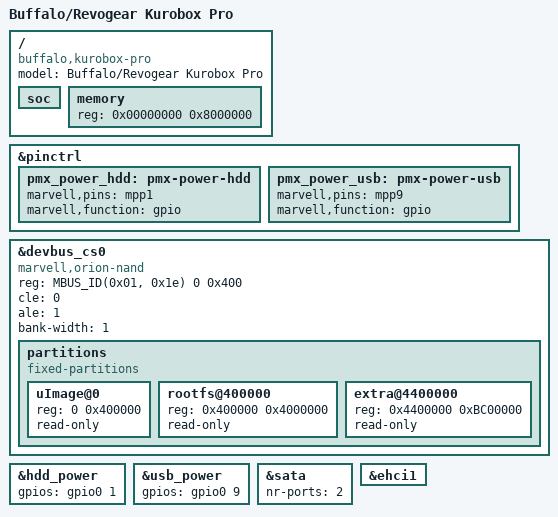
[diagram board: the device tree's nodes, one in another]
/*
 * Device Tree file for Buffalo/Revogear Kurobox Pro
 *
 * Copyright (C) 2016
 * Roger Shimizu <rogershimizu@gmail.com>
 *
 * Based on the board file arch/arm/mach-orion5x/kurobox_pro-setup.c
 * Copyright (C) Ronen Shitrit <rshitrit@marvell.com>
 *
 * This file is dual-licensed: you can use it either under the terms
 * of the GPL or the X11 license, at your option. Note that this dual
 * licensing only applies to this file, and not this project as a
 * whole.
 *
 *  a) This file is free software; you can redistribute it and/or
 *     modify it under the terms of the GNU General Public License as
 *     published by the Free Software Foundation; either version 2 of the
 *     License, or (at your option) any later version.
 *
 *     This file is distributed in the hope that it will be useful,
 *     but WITHOUT ANY WARRANTY; without even the implied warranty of
 *     MERCHANTABILITY or FITNESS FOR A PARTICULAR PURPOSE.  See the
 *     GNU General Public License for more details.
 *
 * Or, alternatively,
 *
 *  b) Permission is hereby granted, free of charge, to any person
 *     obtaining a copy of this software and associated documentation
 *     files (the "Software"), to deal in the Software without
 *     restriction, including without limitation the rights to use,
 *     copy, modify, merge, publish, distribute, sublicense, and/or
 *     sell copies of the Software, and to permit persons to whom the
 *     Software is furnished to do so, subject to the following
 *     conditions:
 *
 *     The above copyright notice and this permission notice shall be
 *     included in all copies or substantial portions of the Software.
 *
 *     THE SOFTWARE IS PROVIDED "AS IS", WITHOUT WARRANTY OF ANY KIND,
 *     EXPRESS OR IMPLIED, INCLUDING BUT NOT LIMITED TO THE WARRANTIES
 *     OF MERCHANTABILITY, FITNESS FOR A PARTICULAR PURPOSE AND
 *     NONINFRINGEMENT. IN NO EVENT SHALL THE AUTHORS OR COPYRIGHT
 *     HOLDERS BE LIABLE FOR ANY CLAIM, DAMAGES OR OTHER LIABILITY,
 *     WHETHER IN AN ACTION OF CONTRACT, TORT OR OTHERWISE, ARISING
 *     FROM, OUT OF OR IN CONNECTION WITH THE SOFTWARE OR THE USE OR
 *     OTHER DEALINGS IN THE SOFTWARE.
 */

/dts-v1/;

#include "orion5x-linkstation.dtsi"
#include <dt-bindings/gpio/gpio.h>

/ {
	model = "Buffalo/Revogear Kurobox Pro";
	compatible = "buffalo,kurobox-pro", "marvell,orion5x-88f5182", "marvell,orion5x";

	soc {
		ranges = <MBUS_ID(0xf0, 0x01) 0 0xf1000000 0x100000>,
				 <MBUS_ID(0x09, 0x00) 0 0xf2200000 0x800>,
				 <MBUS_ID(0x01, 0x0f) 0 0xf4000000 0x40000>,
				 <MBUS_ID(0x01, 0x1e) 0 0xfc000000 0x1000000>;
	};

	memory { /* 128 MB */
		device_type = "memory";
		reg = <0x00000000 0x8000000>;
	};
};

&pinctrl {
	pmx_power_hdd: pmx-power-hdd {
		marvell,pins = "mpp1";
		marvell,function = "gpio";
	};

	pmx_power_usb: pmx-power-usb {
		marvell,pins = "mpp9";
		marvell,function = "gpio";
	};
};

&devbus_cs0 {
	status = "okay";
	compatible = "marvell,orion-nand";
	reg = <MBUS_ID(0x01, 0x1e) 0 0x400>;
	cle = <0>;
	ale = <1>;
	bank-width = <1>;

	partitions {
		compatible = "fixed-partitions";
		#address-cells = <1>;
		#size-cells = <1>;

		uImage@0 { /* 4 MB */
			reg = <0 0x400000>;
			read-only;
		};

		rootfs@400000 { /* 64 MB */
			reg = <0x400000 0x4000000>;
			read-only;
		};

		extra@4400000 { /* 188 MB */
			reg = <0x4400000 0xBC00000>;
			read-only;
		};
	};
};

&hdd_power {
	gpios = <&gpio0 1 GPIO_ACTIVE_HIGH>;
};

&usb_power {
	gpios = <&gpio0 9 GPIO_ACTIVE_HIGH>;
};

&sata {
	nr-ports = <2>;
};

&ehci1 {
	status = "okay";
};
